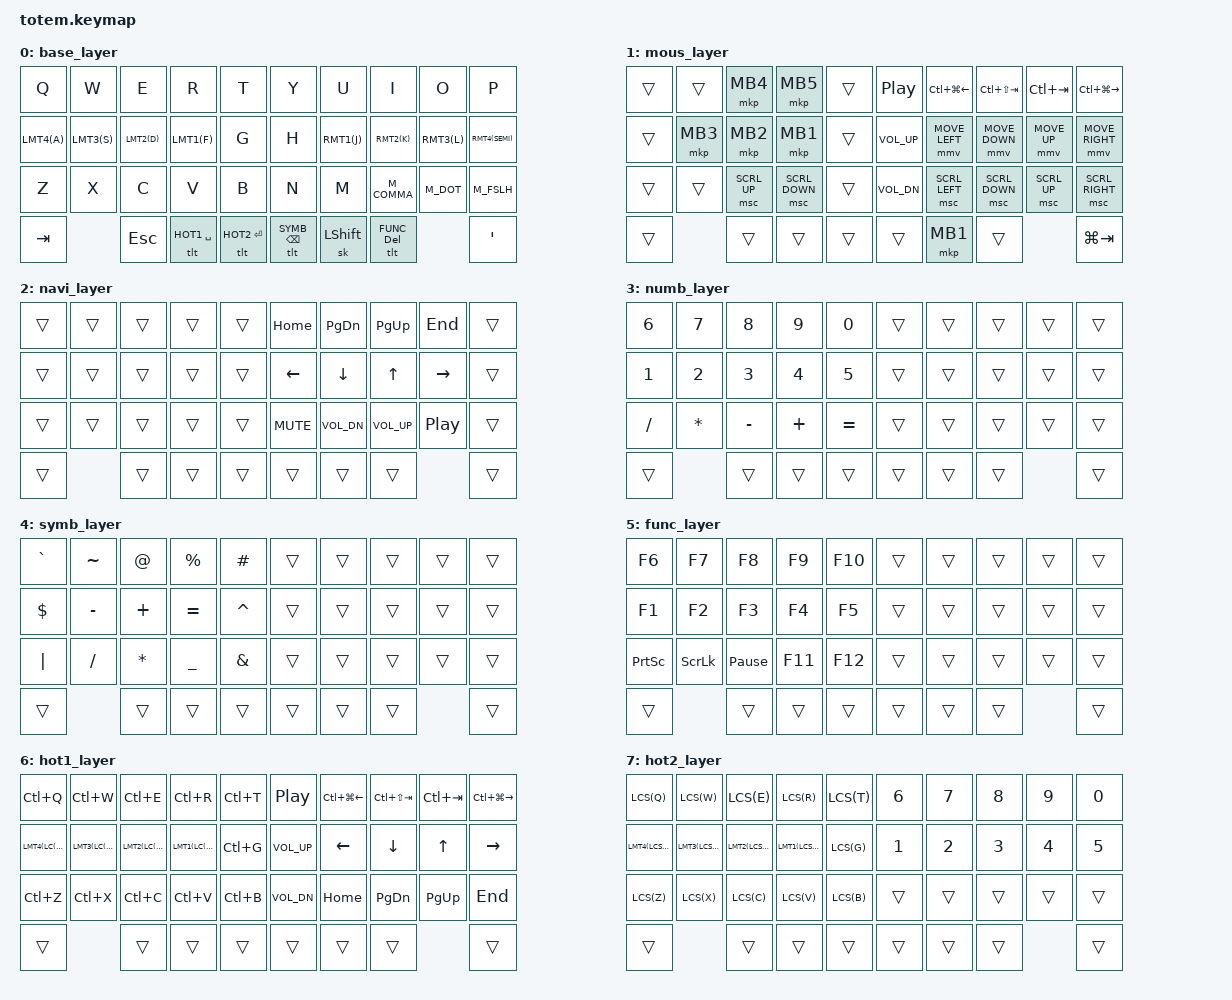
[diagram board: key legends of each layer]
#include <behaviors.dtsi>
#include <dt-bindings/zmk/keys.h>
#include <dt-bindings/zmk/bt.h>
#include <dt-bindings/zmk/outputs.h>

/*=====================*/
/* Mouse               */
/*=====================*/
#define ZMK_POINTING_DEFAULT_MOVE_VAL 2400
#define ZMK_POINTING_DEFAULT_SCRL_VAL 20
#include <dt-bindings/zmk/pointing.h>

&mmv {
  acceleration-exponent = <1>;
  time-to-max-speed-ms = <800>;
};

&msc {
  acceleration-exponent = <0>;
  time-to-max-speed-ms = <0>;
  acceleration-exponent = <2>;
};

/*=====================*/
/* Helper              */
/*=====================*/
#include "./totem_key_position.h"
#include "./totem_macro.h"

/*=====================*/
/* Layer               */
/*=====================*/
#define BASE 0
#define MOUS 1
#define NAVI 2
#define NUMB 3
#define SYMB 4
#define FUNC 5
#define HOT1 6
#define HOT2 7

/*=====================*/
/* Hold Tap            */
/*=====================*/
#define HT        tapping-term-ms = <280>; quick-tap-ms = <180>;
#define HT_BLCD   flavor = "balanced";
#define HT_HOLD   flavor = "hold-preferred";
#define HT_IDLE   require-prior-idle-ms = <120>;
#define HT_LEFT   hold-trigger-key-positions = <KEYS_RIGHT KEYS_ETC>;
#define HT_RIGHT  hold-trigger-key-positions = <KEYS_LEFT KEYS_ETC>;
#define HT_MT     bindings = <&kp>, <&kp>; hold-trigger-on-release;
#define HT_ML     bindings = <&kp>, <&to>; hold-trigger-on-release;
#define HT_LT     bindings = <&mo>, <&kp>;
#define HT_LL     bindings = <&mo>, <&to>;

ZMK_HOLD_TAP(lmt, HT HT_LEFT  HT_MT HT_BLCD HT_IDLE)
ZMK_HOLD_TAP(lml, HT HT_LEFT  HT_ML HT_BLCD HT_IDLE)
ZMK_HOLD_TAP(llt, HT HT_LEFT  HT_LT HT_BLCD HT_IDLE)
ZMK_HOLD_TAP(rmt, HT HT_RIGHT HT_MT HT_BLCD HT_IDLE)
ZMK_HOLD_TAP(rml, HT HT_RIGHT HT_ML HT_BLCD HT_IDLE)
ZMK_HOLD_TAP(rlt, HT HT_RIGHT HT_LT HT_BLCD HT_IDLE)
ZMK_HOLD_TAP(tmt, HT          HT_MT HT_HOLD        )
ZMK_HOLD_TAP(tlt, HT          HT_LT HT_BLCD        )
ZMK_HOLD_TAP(tll, HT          HT_LL HT_BLCD        )

/*=====================*/
/* Mod Morp            */
/*=====================*/
ZMK_SFT_MORPH(M_COMMA, &kp COMMA, &kp QMARK)
ZMK_SFT_MORPH(M_DOT,   &kp DOT,   &kp EXCL)
ZMK_SFT_MORPH(M_FSLH,  &kp FSLH,  &kp BSLH)

/*=====================*/
/* Alias               */
/*=====================*/
#define __________ &trans

#define MMV_L &mmv MOVE_LEFT
#define MMV_R &mmv MOVE_RIGHT
#define MMV_U &mmv MOVE_UP
#define MMV_D &mmv MOVE_DOWN
#define MSC_L &msc SCRL_LEFT
#define MSC_R &msc SCRL_RIGHT
#define MSC_U &msc SCRL_UP
#define MSC_D &msc SCRL_DOWN
#define WIN_T &kp LG(TAB)
#define WIN_L &kp LC(LG(LEFT))
#define WIN_R &kp LC(LG(RIGHT))
#define TAB_L &kp LC(LS(TAB))
#define TAB_R &kp LC(TAB)

#define KP_LA0 &kp TAB
#define KP_LH2 &kp ESC
#define KP_LH1 &tlt HOT1 SPACE
#define KP_LH0 &tlt HOT2 RET

#define KP_RH0 &tlt SYMB BSPC
#define KP_RH1 &sk LSHFT
#define KP_RH2 &tlt FUNC DEL
#define KP_RA0 &kp APOS

#define LCS(keycode) LC(LS(keycode))

#define LMT1(keycode) &lmt LSHFT keycode
#define LMT2(keycode) &lmt LCTRL keycode
#define LMT3(keycode) &lmt LALT keycode
#define LMT4(keycode) &lmt LGUI keycode

#define LMT43(keycode) &lmt LA(LGUI) keycode
#define LMT32(keycode) &lmt LC(LALT) keycode
#define LMT21(keycode) &lmt LS(LCTRL) keycode
#define LMT31(keycode) &lmt LS(LALT) keycode

#define LML43(keycode) &lml LA(LGUI) keycode
#define LML32(keycode) &lml LC(LALT) keycode
#define LML21(keycode) &lml LS(LCTRL) keycode
#define LML31(keycode) &lml LS(LALT) keycode

#define RMT1(keycode) &rmt LSHFT keycode
#define RMT2(keycode) &rmt LCTRL keycode
#define RMT3(keycode) &rmt LALT keycode
#define RMT4(keycode) &rmt LGUI keycode

#define RMT12(keycode) &rmt LS(LCTRL) keycode
#define RMT23(keycode) &rmt LC(LALT) keycode
#define RMT34(keycode) &rmt LA(LGUI) keycode
#define RMT13(keycode) &rmt LS(LALT) keycode

#define RML12(keycode) &rml LS(LCTRL) keycode
#define RML23(keycode) &rml LC(LALT) keycode
#define RML34(keycode) &rml LA(LGUI) keycode
#define RML13(keycode) &rml LS(LALT) keycode

/*=====================*/
/* Keymap              */
/*=====================*/
ZMK_LAYER(base_layer, /*
╭────────────┬────────────┬────────────┬────────────┬────────────╮╭────────────┬────────────┬────────────┬────────────┬────────────╮
*/&kp Q        &kp W        &kp E        &kp R        &kp T         &kp Y        &kp U        &kp I        &kp O        &kp P     /*
├────────────┼────────────┼────────────┼────────────┼────────────┤├────────────┼────────────┼────────────┼────────────┼────────────┤
*/LMT4(A)      LMT3(S)      LMT2(D)      LMT1(F)      &kp G         &kp H        RMT1(J)      RMT2(K)      RMT3(L)      RMT4(SEMI)/*
├────────────┼────────────┼────────────┼────────────┼────────────┤├────────────┼────────────┼────────────┼────────────┼────────────┤
*/&kp Z        &kp X        &kp C        &kp V        &kp B         &kp N        &kp M        &M_COMMA     &M_DOT       &M_FSLH   /*
╰────────────┴────────────┴────────────┴────────────┴────────────╯╰────────────┴────────────┴────────────┴────────────┴────────────╯
╭────────────╮            ╭────────────┬────────────┬────────────╮╭────────────┬────────────┬────────────╮            ╭────────────╮
*/KP_LA0                    KP_LH2       KP_LH1       KP_LH0        KP_RH0       KP_RH1       KP_RH2                    KP_RA0    /*
╰────────────╯            ╰────────────┴────────────┴────────────╯╰────────────┴────────────┴────────────╯            ╰────────────╯
*/)

ZMK_LAYER(mous_layer, /*
╭────────────┬────────────┬────────────┬────────────┬────────────╮╭────────────┬────────────┬────────────┬────────────┬────────────╮
*/__________   __________   &mkp MB4     &mkp MB5     __________    &kp C_PP     WIN_L        TAB_L        TAB_R        WIN_R     /*
├────────────┼────────────┼────────────┼────────────┼────────────┤├────────────┼────────────┼────────────┼────────────┼────────────┤
*/__________   &mkp MB3     &mkp MB2     &mkp MB1     __________   &kp C_VOL_UP  MMV_L        MMV_D        MMV_U        MMV_R     /*
├────────────┼────────────┼────────────┼────────────┼────────────┤├────────────┼────────────┼────────────┼────────────┼────────────┤
*/__________   __________   MSC_U        MSC_D        __________   &kp C_VOL_DN  MSC_L        MSC_D        MSC_U        MSC_R     /*
╰────────────┴────────────┴────────────┴────────────┴────────────╯╰────────────┴────────────┴────────────┴────────────┴────────────╯
╭────────────╮            ╭────────────┬────────────┬────────────╮╭────────────┬────────────┬────────────╮            ╭────────────╮
*/__________                __________   __________   __________    __________   &mkp MB1     __________                WIN_T     /*
╰────────────╯            ╰────────────┴────────────┴────────────╯╰────────────┴────────────┴────────────╯            ╰────────────╯
*/)

ZMK_LAYER(navi_layer, /*
╭────────────┬────────────┬────────────┬────────────┬────────────╮╭────────────┬────────────┬────────────┬────────────┬────────────╮
*/__________   __________   __________   __________   __________    &kp HOME     &kp PG_DN    &kp PG_UP    &kp END      __________/*
├────────────┼────────────┼────────────┼────────────┼────────────┤├────────────┼────────────┼────────────┼────────────┼────────────┤
*/__________   __________   __________   __________   __________    &kp LEFT     &kp DOWN     &kp UP       &kp RIGHT    __________/*
├────────────┼────────────┼────────────┼────────────┼────────────┤├────────────┼────────────┼────────────┼────────────┼────────────┤
*/__________   __________   __________   __________   __________    &kp C_MUTE  &kp C_VOL_DN &kp C_VOL_UP  &kp C_PP      __________/*
╰────────────┴────────────┴────────────┴────────────┴────────────╯╰────────────┴────────────┴────────────┴────────────┴────────────╯
╭────────────╮            ╭────────────┬────────────┬────────────╮╭────────────┬────────────┬────────────╮            ╭────────────╮
*/__________                __________   __________   __________    __________   __________   __________                __________/*
╰────────────╯            ╰────────────┴────────────┴────────────╯╰────────────┴────────────┴────────────╯            ╰────────────╯
*/)

ZMK_LAYER(numb_layer, /*
╭────────────┬────────────┬────────────┬────────────┬────────────╮╭────────────┬────────────┬────────────┬────────────┬────────────╮
*/&kp N6       &kp N7       &kp N8       &kp N9       &kp N0        __________   __________   __________   __________   __________/*
├────────────┼────────────┼────────────┼────────────┼────────────┤├────────────┼────────────┼────────────┼────────────┼────────────┤
*/&kp N1       &kp N2       &kp N3       &kp N4       &kp N5        __________   __________   __________   __________   __________/*
├────────────┼────────────┼────────────┼────────────┼────────────┤├────────────┼────────────┼────────────┼────────────┼────────────┤
*/&kp FSLH     &kp STAR     &kp MINUS    &kp PLUS     &kp EQUAL     __________   __________   __________   __________   __________/*
╰────────────┴────────────┴────────────┴────────────┴────────────╯╰────────────┴────────────┴────────────┴────────────┴────────────╯
╭────────────╮            ╭────────────┬────────────┬────────────╮╭────────────┬────────────┬────────────╮            ╭────────────╮
*/__________                __________   __________   __________    __________   __________   __________                __________/*
╰────────────╯            ╰────────────┴────────────┴────────────╯╰────────────┴────────────┴────────────╯            ╰────────────╯
*/)

ZMK_LAYER(symb_layer, /*
╭────────────┬────────────┬────────────┬────────────┬────────────╮╭────────────┬────────────┬────────────┬────────────┬────────────╮
*/&kp GRAVE    &kp TILDE    &kp AT       &kp PRCNT    &kp HASH      __________   __________   __________   __________   __________/*
├────────────┼────────────┼────────────┼────────────┼────────────┤├────────────┼────────────┼────────────┼────────────┼────────────┤
*/&kp DLLR     &kp MINUS    &kp PLUS     &kp EQUAL    &kp CARET     __________   __________   __________   __________   __________/*
├────────────┼────────────┼────────────┼────────────┼────────────┤├────────────┼────────────┼────────────┼────────────┼────────────┤
*/&kp PIPE     &kp FSLH     &kp STAR     &kp UNDER    &kp AMPS      __________   __________   __________   __________   __________/*
╰────────────┴────────────┴────────────┴────────────┴────────────╯╰────────────┴────────────┴────────────┴────────────┴────────────╯
╭────────────╮            ╭────────────┬────────────┬────────────╮╭────────────┬────────────┬────────────╮            ╭────────────╮
*/__________                __________   __________   __________    __________   __________   __________                __________/*
╰────────────╯            ╰────────────┴────────────┴────────────╯╰────────────┴────────────┴────────────╯            ╰────────────╯
*/)

ZMK_LAYER(func_layer, /*
╭────────────┬────────────┬────────────┬────────────┬────────────╮╭────────────┬────────────┬────────────┬────────────┬────────────╮
*/&kp F6       &kp F7       &kp F8       &kp F9       &kp F10       __________   __________   __________   __________   __________/*
├────────────┼────────────┼────────────┼────────────┼────────────┤├────────────┼────────────┼────────────┼────────────┼────────────┤
*/&kp F1       &kp F2       &kp F3       &kp F4       &kp F5        __________   __________   __________   __________   __________/*
├────────────┼────────────┼────────────┼────────────┼────────────┤├────────────┼────────────┼────────────┼────────────┼────────────┤
*/&kp PSCRN    &kp SLCK  &kp PAUSE_BREAK &kp F11      &kp F12       __________   __________   __________   __________   __________/*
╰────────────┴────────────┴────────────┴────────────┴────────────╯╰────────────┴────────────┴────────────┴────────────┴────────────╯
╭────────────╮            ╭────────────┬────────────┬────────────╮╭────────────┬────────────┬────────────╮            ╭────────────╮
*/__________                __________   __________   __________    __________   __________   __________                __________/*
╰────────────╯            ╰────────────┴────────────┴────────────╯╰────────────┴────────────┴────────────╯            ╰────────────╯
*/)

ZMK_LAYER(hot1_layer, /*
╭────────────┬────────────┬────────────┬────────────┬────────────╮╭────────────┬────────────┬────────────┬────────────┬────────────╮
*/&kp LC(Q)    &kp LC(W)    &kp LC(E)    &kp LC(R)    &kp LC(T)     &kp C_PP     WIN_L        TAB_L        TAB_R        WIN_R     /*
├────────────┼────────────┼────────────┼────────────┼────────────┤├────────────┼────────────┼────────────┼────────────┼────────────┤
*/LMT4(LC(A))  LMT3(LC(S))  LMT2(LC(D))  LMT1(LC(F))  &kp LC(G)    &kp C_VOL_UP  &kp LEFT     &kp DOWN     &kp UP       &kp RIGHT /*
├────────────┼────────────┼────────────┼────────────┼────────────┤├────────────┼────────────┼────────────┼────────────┼────────────┤
*/&kp LC(Z)    &kp LC(X)    &kp LC(C)    &kp LC(V)    &kp LC(B)    &kp C_VOL_DN  &kp HOME     &kp PG_DN    &kp PG_UP    &kp END   /*
╰────────────┴────────────┴────────────┴────────────┴────────────╯╰────────────┴────────────┴────────────┴────────────┴────────────╯
╭────────────╮            ╭────────────┬────────────┬────────────╮╭────────────┬────────────┬────────────╮            ╭────────────╮
*/__________                __________   __________   __________    __________   __________   __________                __________/*
╰────────────╯            ╰────────────┴────────────┴────────────╯╰────────────┴────────────┴────────────╯            ╰────────────╯
*/)


ZMK_LAYER(hot2_layer, /*
╭────────────┬────────────┬────────────┬────────────┬────────────╮╭────────────┬────────────┬────────────┬────────────┬────────────╮
*/&kp LCS(Q)   &kp LCS(W)   &kp LCS(E)   &kp LCS(R)   &kp LCS(T)    &kp N6       &kp N7       &kp N8       &kp N9       &kp N0    /*
├────────────┼────────────┼────────────┼────────────┼────────────┤├────────────┼────────────┼────────────┼────────────┼────────────┤
*/LMT4(LCS(A)) LMT3(LCS(S)) LMT2(LCS(D)) LMT1(LCS(F)) &kp LCS(G)    &kp N1       &kp N2       &kp N3       &kp N4       &kp N5    /*
├────────────┼────────────┼────────────┼────────────┼────────────┤├────────────┼────────────┼────────────┼────────────┼────────────┤
*/&kp LCS(Z)   &kp LCS(X)   &kp LCS(C)   &kp LCS(V)   &kp LCS(B)    __________   __________   __________   __________   __________/*
╰────────────┴────────────┴────────────┴────────────┴────────────╯╰────────────┴────────────┴────────────┴────────────┴────────────╯
╭────────────╮            ╭────────────┬────────────┬────────────╮╭────────────┬────────────┬────────────╮            ╭────────────╮
*/__________                __________   __________   __________    __________   __________   __________                __________/*
╰────────────╯            ╰────────────┴────────────┴────────────╯╰────────────┴────────────┴────────────╯            ╰────────────╯
*/)

/*=====================*/
/* Combo               */
/*=====================*/
#define COMBO_TERM_FAST 18
#define COMBO_TERM_SLOW 30
#define COMBO_IDLE_FAST 150
#define COMBO_IDLE_SLOW 50

/*
╭────────────┬────────────┬────────────┬────────────┬────────────╮╭────────────┬────────────┬────────────┬────────────┬────────────╮
│    LT4     │    LT3     │    LT2     │    LT1     │    LT0     ││    RT0     │    RT1     │    RT2     │    RT3     │    RT4     │
├────────────┼────────────┼────────────┼────────────┼────────────┤├────────────┼────────────┼────────────┼────────────┼────────────┤
│    LM4    Del   LM3    Tab   LM2    Bspc  LM1     │    LM0     ││    RM0     │    RM1    MOUS  RM2    NAVI  RM3     │    RM4     │
├────────────┼────────────┼────────────┼────────────┼────────────┤├────────────┼────────────┼────────────┼────────────┼────────────┤
│    LB4     │    LB3     │    LB2     │    LB1     │    LB0     ││    RB0     │    RB1     │    RB2     │    RB3     │    RB4     │
╰────────────┴────────────┴────────────┴────────────┴────────────╯╰────────────┴────────────┴────────────┴────────────┴────────────╯
╭────────────╮            ╭────────────┬────────────┬────────────╮╭────────────┬────────────┬────────────╮            ╭────────────╮
│    LA0     │            │    LH2     │    LH1     │    LH0     ││    RH0     │    RH1     │    RH2     │            │    RA0     │
╰────────────╯            ╰────────────┴────────────┴────────────╯╰────────────┴────────────┴────────────╯            ╰────────────╯
*/

// Left horizontal
ZMK_COMBO(lh_lbkt   , &kp LBKT        , LT4 LT3, BASE MOUS NAVI NUMB SYMB, COMBO_TERM_FAST, COMBO_IDLE_FAST)
ZMK_COMBO(lh_lpar   , &kp LPAR        , LT3 LT2, BASE MOUS NAVI NUMB SYMB, COMBO_TERM_FAST, COMBO_IDLE_FAST)
ZMK_COMBO(lh_rpar   , &kp RPAR        , LT2 LT1, BASE MOUS NAVI NUMB SYMB, COMBO_TERM_FAST, COMBO_IDLE_FAST)
ZMK_COMBO(lh_rbkt   , &kp RBKT        , LT1 LT0, BASE MOUS NAVI NUMB SYMB, COMBO_TERM_FAST, COMBO_IDLE_FAST)

ZMK_COMBO(lh_del    , LMT43(DEL)      , LM4 LM3, BASE MOUS NAVI NUMB SYMB, COMBO_TERM_FAST, COMBO_IDLE_FAST)
ZMK_COMBO(lh_NUMB   , LML32(NUMB)     , LM3 LM2, BASE MOUS NAVI      SYMB, COMBO_TERM_FAST, COMBO_IDLE_FAST)
ZMK_COMBO(lh_SYMB   , LML21(SYMB)     , LM2 LM1, BASE MOUS NAVI NUMB     , COMBO_TERM_FAST, COMBO_IDLE_FAST)
ZMK_COMBO(lh_bspc   , &kp BSPC        , LM1 LM0, BASE MOUS NAVI NUMB SYMB, COMBO_TERM_FAST, COMBO_IDLE_FAST)
ZMK_COMBO(lh_BASE   , LML31(BASE)     , LM3 LM1,      MOUS NAVI NUMB SYMB, COMBO_TERM_FAST, COMBO_IDLE_FAST)
ZMK_COMBO(lh_esc    , LMT31(ESC)      , LM3 LM1, BASE                    , COMBO_TERM_FAST, COMBO_IDLE_FAST)

ZMK_COMBO(lh_lt     , &kp LT          , LB4 LB3, BASE MOUS NAVI NUMB SYMB, COMBO_TERM_FAST, COMBO_IDLE_FAST)
ZMK_COMBO(lh_lbrc   , &kp LBRC        , LB3 LB2, BASE MOUS NAVI NUMB SYMB, COMBO_TERM_FAST, COMBO_IDLE_FAST)
ZMK_COMBO(lh_rbrc   , &kp RBRC        , LB2 LB1, BASE MOUS NAVI NUMB SYMB, COMBO_TERM_FAST, COMBO_IDLE_FAST)
ZMK_COMBO(lh_gt     , &kp GT          , LB1 LB0, BASE MOUS NAVI NUMB SYMB, COMBO_TERM_FAST, COMBO_IDLE_FAST)

// Right horizontal
ZMK_COMBO(rh_lbkt   , &kp LBKT        , RT1 RT2, BASE MOUS NAVI NUMB SYMB, COMBO_TERM_FAST, COMBO_IDLE_FAST)
ZMK_COMBO(rh_rbkt   , &kp RBKT        , RT2 RT3, BASE MOUS NAVI NUMB SYMB, COMBO_TERM_FAST, COMBO_IDLE_FAST)

ZMK_COMBO(rh_MOUS   , RML12(MOUS)     , RM1 RM2, BASE      NAVI NUMB SYMB, COMBO_TERM_FAST, COMBO_IDLE_FAST)
ZMK_COMBO(rh_NAVI   , RML23(NAVI)     , RM2 RM3, BASE MOUS      NUMB SYMB, COMBO_TERM_FAST, COMBO_IDLE_FAST)
ZMK_COMBO(rh_BASE   , RML13(BASE)     , RM1 RM3,      MOUS NAVI NUMB SYMB, COMBO_TERM_FAST, COMBO_IDLE_FAST)
ZMK_COMBO(rh_lang   , RMT13(LC(SPACE)), RM1 RM3, BASE                    , COMBO_TERM_FAST, COMBO_IDLE_FAST)

ZMK_COMBO(rh_lt     , &kp LT          , RB1 RB2, BASE MOUS NAVI NUMB SYMB, COMBO_TERM_FAST, COMBO_IDLE_FAST)
ZMK_COMBO(rh_gt     , &kp GT          , RB2 RB3, BASE MOUS NAVI NUMB SYMB, COMBO_TERM_FAST, COMBO_IDLE_FAST)

// Left vertical
ZMK_COMBO(lv_equal  , &kp EQUAL       , LT1 LM1, BASE MOUS NAVI NUMB SYMB, COMBO_TERM_SLOW, COMBO_IDLE_SLOW)
ZMK_COMBO(lv_under  , &kp UNDER       , LM1 LB1, BASE MOUS NAVI NUMB SYMB, COMBO_TERM_SLOW, COMBO_IDLE_SLOW)
ZMK_COMBO(lv_plus   , &kp PLUS        , LT2 LM2, BASE MOUS NAVI NUMB SYMB, COMBO_TERM_SLOW, COMBO_IDLE_SLOW)
ZMK_COMBO(lv_star   , &kp STAR        , LM2 LB2, BASE MOUS NAVI NUMB SYMB, COMBO_TERM_SLOW, COMBO_IDLE_SLOW)
ZMK_COMBO(lv_minus  , &kp MINUS       , LT3 LM3, BASE MOUS NAVI NUMB SYMB, COMBO_TERM_SLOW, COMBO_IDLE_SLOW)
ZMK_COMBO(lv_fslh   , &kp FSLH        , LM3 LB3, BASE MOUS NAVI NUMB SYMB, COMBO_TERM_SLOW, COMBO_IDLE_SLOW)

// Both horizontal
ZMK_COMBO(bh_boot   , &bootloader     , LH2 RH2, BASE MOUS NAVI NUMB SYMB, COMBO_TERM_SLOW, COMBO_IDLE_SLOW)
ZMK_COMBO(bh_studio , &studio_unlock  , LA0 RA0, BASE MOUS NAVI NUMB SYMB, COMBO_TERM_SLOW, COMBO_IDLE_SLOW)
